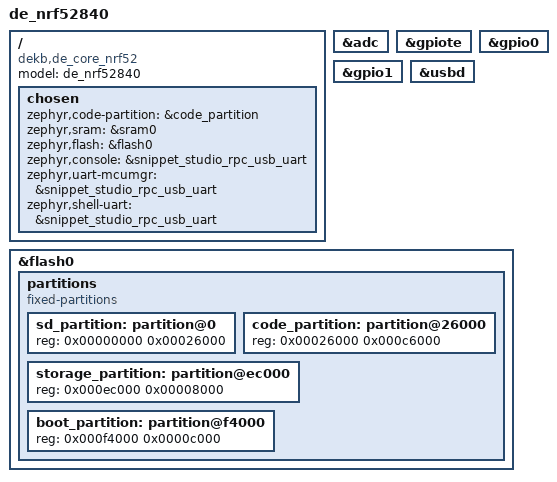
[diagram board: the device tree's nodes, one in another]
/*
 * Copyright (c) 2026 DEKB
 *
 * SPDX-License-Identifier: MIT
 */

/dts-v1/;
#include <nordic/nrf52840_qiaa.dtsi>

/ {
    model = "de_nrf52840";
    compatible = "dekb,de_core_nrf52";

    chosen {
        zephyr,code-partition = &code_partition;
        zephyr,sram = &sram0;
        zephyr,flash = &flash0;
        zephyr,console = &snippet_studio_rpc_usb_uart;
        zephyr,uart-mcumgr = &snippet_studio_rpc_usb_uart;
        zephyr,shell-uart = &snippet_studio_rpc_usb_uart;
    };

};

&adc {
    status = "okay";
};

&gpiote {
    status = "okay";
};

&gpio0 {
    status = "okay";
};

&gpio1 {
    status = "okay";
};

zephyr_udc0: &usbd {
    status = "okay";
};

&flash0 {
    /*
     * For more information, see:
     * http://docs.zephyrproject.org/latest/devices/dts/flash_partitions.html
     */
    partitions {
        compatible = "fixed-partitions";
        #address-cells = <1>;
        #size-cells = <1>;

        sd_partition: partition@0 {
            reg = <0x00000000 0x00026000>;
        };
        code_partition: partition@26000 {
            reg = <0x00026000 0x000c6000>;
        };

        /*
         * The flash starting at 0x000ec000 and ending at
         * 0x000f3fff is reserved for use by the application.
         */

        /*
         * Storage partition will be used by FCB/LittleFS/NVS
         * if enabled.
         */
        storage_partition: partition@ec000 {
            reg = <0x000ec000 0x00008000>;
        };

        boot_partition: partition@f4000 {
            reg = <0x000f4000 0x0000c000>;
        };
    };
};
